# STC32G144K246 register map
Vendor: STC; File version: 2.0
Registers are 8-bit, read-write, no defined reset value unless marked. A register's access mark holds for its fields unless they carry their own. Offsets are from the block's base; [hi:lo] are bit positions; {n}, {i} and the like mark numbered series; 'fields as' and 'values as' point back to an identical list.

## DMA — DMA 公共中断与各通道配置、状态
Base 0x007EF520
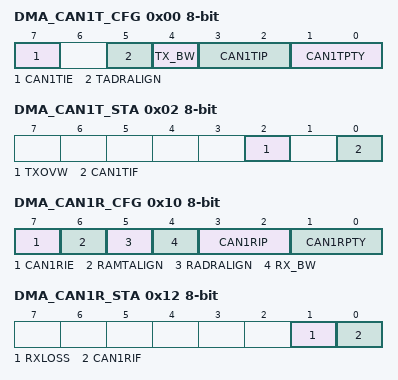
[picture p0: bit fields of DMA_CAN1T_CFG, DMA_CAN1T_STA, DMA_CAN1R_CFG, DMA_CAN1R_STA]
0x00 DMA_CAN1T_CFG ro — CAN1T_DMA配置寄存器
  [7] CAN1TIE — CANnT_DMA 中断使能控制位（n=1/2）
    0=禁止CANnT_DMA 中断; 1=允许CANnT_DMA 中断
  [5] TADRALIGN — CANn 发送DMA 数据对齐控制（n=1/2）
    0=数据不对齐。DMA 缓冲区中的任意两帧数据之间没有空白，数据连续; 1=数据对齐。DMA 缓冲区中的数据必须按DMA_CANnT_FRM 寄存器设置值进行对齐。
  [4] TX_BW — CANn 发送DMA 数据宽度（n=1/2）
    0=8 位宽度（1 字节）; 1=32 位宽度（4 字节）
  [3:2] CAN1TIP — CANnT_DMA 中断优先级控制位（n=1/2）
    0=最低级（0）; 1=较低级（1）; 2=较高级（2）; 3=最高级（3）
  [1:0] CAN1TPTY — CANnT_DMA 数据总线访问优先级控制位（n=1/2）
    0=最低级（0）; 1=较低级（1）; 2=较高级（2）; 3=最高级（3）
0x02 DMA_CAN1T_STA ro — CAN1T_DMA状态寄存器
  [2] TXOVW — 尚未自动匹配到此字段的独立说明；请查看下方章节说明。
  [0] CAN1TIF — CANnT_DMA 中断请求标志位，标志位需软件清零（n=1/2）
0x10 DMA_CAN1R_CFG ro — CAN1R_DMA配置寄存器
  [7] CAN1RIE — CANnR_DMA 中断使能控制位（n=1/2）
    0=禁止CANnR_DMA 中断; 1=允许CANnR_DMA 中断
  [6] RAMTALIGN — CANn 接收DMA 总字节对齐控制（n=1/2）
    0=当接收的数据总字节等于DMA_CANnR_AMT 所设置的值时，DMA 接收完成; 1=当接收的数据总字节大于或等于DMA_CANnR_AMT 所设置的值，且当前帧的所有数据都已传
  [5] RADRALIGN — CANn 接收DMA 数据对齐控制（n=1/2）
    0=数据不对齐。DMA 缓冲区中的任意两帧数据之间没有空白，数据连续; 1=数据对齐。DMA 缓冲区中的数据必须按DMA_CANnR_FRM 寄存器设置值进行对齐。
  [4] RX_BW — CANn 接收DMA 数据宽度（n=1/2）
    0=8 位宽度（1 字节）; 1=32 位宽度（4 字节）
  [3:2] CAN1RIP — CANnR_DMA 中断优先级控制位（n=1/2）
    0=最低级（0）; 1=较低级（1）; 2=较高级（2）; 3=最高级（3）
  [1:0] CAN1RPTY — CANnR_DMA 数据总线访问优先级控制位（n=1/2）
    0=最低级（0）; 1=较低级（1）; 2=较高级（2）; 3=最高级（3）
0x12 DMA_CAN1R_STA ro — CAN1R_DMA状态寄存器
  [1] RXLOSS — 尚未自动匹配到此字段的独立说明；请查看下方章节说明。
  [0] CAN1RIF — CANnR_DMA 中断请求标志位，标志位需软件清零（n=1/2）
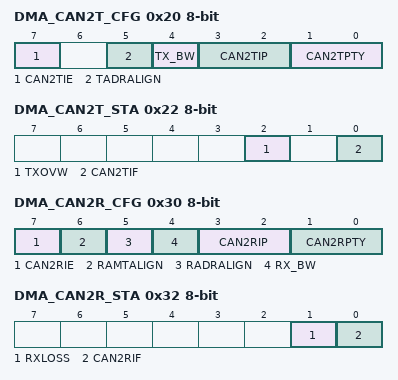
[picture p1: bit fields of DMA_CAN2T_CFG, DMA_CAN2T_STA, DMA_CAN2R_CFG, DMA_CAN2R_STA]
0x20 DMA_CAN2T_CFG ro — CAN2T_DMA配置寄存器
  [7] CAN2TIE — CANnT_DMA 中断使能控制位（n=1/2）
    0=禁止CANnT_DMA 中断; 1=允许CANnT_DMA 中断
  [5] TADRALIGN — CANn 发送DMA 数据对齐控制（n=1/2）
    values as DMA_CAN1T_CFG.TADRALIGN
  [4] TX_BW — CANn 发送DMA 数据宽度（n=1/2）
    0=8 位宽度（1 字节）; 1=32 位宽度（4 字节）
  [3:2] CAN2TIP — CANnT_DMA 中断优先级控制位（n=1/2）
    0=最低级（0）; 1=较低级（1）; 2=较高级（2）; 3=最高级（3）
  [1:0] CAN2TPTY — CANnT_DMA 数据总线访问优先级控制位（n=1/2）
    0=最低级（0）; 1=较低级（1）; 2=较高级（2）; 3=最高级（3）
0x22 DMA_CAN2T_STA ro — CAN2T_DMA状态寄存器
  [2] TXOVW — 尚未自动匹配到此字段的独立说明；请查看下方章节说明。
  [0] CAN2TIF — CANnT_DMA 中断请求标志位，标志位需软件清零（n=1/2）
0x30 DMA_CAN2R_CFG ro — CAN2R_DMA配置寄存器
  [7] CAN2RIE — CANnR_DMA 中断使能控制位（n=1/2）
    0=禁止CANnR_DMA 中断; 1=允许CANnR_DMA 中断
  [6] RAMTALIGN — CANn 接收DMA 总字节对齐控制（n=1/2）
    values as DMA_CAN1R_CFG.RAMTALIGN
  [5] RADRALIGN — CANn 接收DMA 数据对齐控制（n=1/2）
    values as DMA_CAN1R_CFG.RADRALIGN
  [4] RX_BW — CANn 接收DMA 数据宽度（n=1/2）
    0=8 位宽度（1 字节）; 1=32 位宽度（4 字节）
  [3:2] CAN2RIP — CANnR_DMA 中断优先级控制位（n=1/2）
    0=最低级（0）; 1=较低级（1）; 2=较高级（2）; 3=最高级（3）
  [1:0] CAN2RPTY — CANnR_DMA 数据总线访问优先级控制位（n=1/2）
    0=最低级（0）; 1=较低级（1）; 2=较高级（2）; 3=最高级（3）
0x32 DMA_CAN2R_STA ro — CAN2R_DMA状态寄存器
  [1] RXLOSS — 尚未自动匹配到此字段的独立说明；请查看下方章节说明。
  [0] CAN2RIF — CANnR_DMA 中断请求标志位，标志位需软件清零（n=1/2）
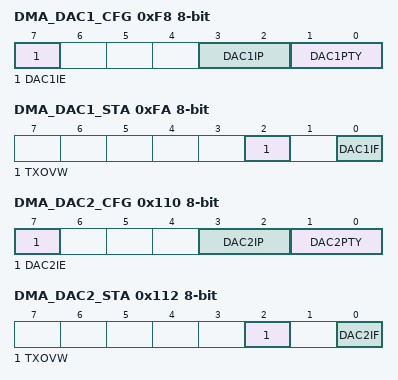
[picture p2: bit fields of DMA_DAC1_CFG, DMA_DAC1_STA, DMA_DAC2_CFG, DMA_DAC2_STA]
0xF8 DMA_DAC1_CFG ro — DAC1_DMA配置寄存器
  [7] DAC1IE — DACn_DMA 中断使能控制位（n=1/2）
    0=禁止DACn_DMA 中断; 1=允许DACn_DMA 中断
  [3:2] DAC1IP — DACn_DMA 中断优先级控制位（n=1/2）
    0=最低级（0）; 1=较低级（1）; 2=较高级（2）; 3=最高级（3）
  [1:0] DAC1PTY — DACn_DMA 数据总线访问优先级控制位（n=1/2）
    0=最低级（0）; 1=较低级（1）; 2=较高级（2）; 3=最高级（3）
0xFA DMA_DAC1_STA ro — DAC1_DMA状态寄存器
  [2] TXOVW — 尚未自动匹配到此字段的独立说明；请查看下方章节说明。
  [0] DAC1IF — DACn_DMA 中断请求标志位，标志位需软件清零（n=1/2）
0x110 DMA_DAC2_CFG ro — DAC2_DMA配置寄存器
  [7] DAC2IE — DACn_DMA 中断使能控制位（n=1/2）
    0=禁止DACn_DMA 中断; 1=允许DACn_DMA 中断
  [3:2] DAC2IP — DACn_DMA 中断优先级控制位（n=1/2）
    0=最低级（0）; 1=较低级（1）; 2=较高级（2）; 3=最高级（3）
  [1:0] DAC2PTY — DACn_DMA 数据总线访问优先级控制位（n=1/2）
    0=最低级（0）; 1=较低级（1）; 2=较高级（2）; 3=最高级（3）
0x112 DMA_DAC2_STA ro — DAC2_DMA状态寄存器
  [2] TXOVW — 尚未自动匹配到此字段的独立说明；请查看下方章节说明。
  [0] DAC2IF — DACn_DMA 中断请求标志位，标志位需软件清零（n=1/2）
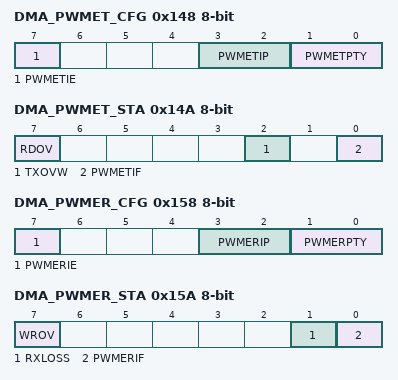
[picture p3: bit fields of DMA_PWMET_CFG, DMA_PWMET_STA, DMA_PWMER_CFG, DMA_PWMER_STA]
0x148 DMA_PWMET_CFG ro — PWMET_DMA配置寄存器
  [7] PWMETIE — PWMnT_DMA 中断使能控制位（n=A/C/E）
    0=禁止PWMnT_DMA 中断; 1=允许PWMnT_DMA 中断
  [3:2] PWMETIP — PWMnT_DMA 中断优先级控制位（n=A/C/E）
    0=最低级（0）; 1=较低级（1）; 2=较高级（2）; 3=最高级（3）
  [1:0] PWMETPTY — PWMnT_DMA 数据总线访问优先级控制位（n=A/C/E）
    0=最低级（0）; 1=较低级（1）; 2=较高级（2）; 3=最高级（3）
0x14A DMA_PWMET_STA ro — PWMET_DMA状态寄存器
  [7] RDOV — 尚未自动匹配到此字段的独立说明；请查看下方章节说明。
  [2] TXOVW — 尚未自动匹配到此字段的独立说明；请查看下方章节说明。
  [0] PWMETIF — PWMnT_DMA 中断请求标志位，标志位需软件清零（n=A/C/E）
0x158 DMA_PWMER_CFG ro — PWMER_DMA配置寄存器
  [7] PWMERIE — PWMnR_DMA 中断使能控制位（n=A/C/E）
    0=禁止PWMnR_DMA 中断; 1=允许PWMnR_DMA 中断
  [3:2] PWMERIP — PWMnR_DMA 中断优先级控制位（n=A/C/E）
    0=最低级（0）; 1=较低级（1）; 2=较高级（2）; 3=最高级（3）
  [1:0] PWMERPTY — PWMnR_DMA 数据总线访问优先级控制位（n=A/C/E）
    0=最低级（0）; 1=较低级（1）; 2=较高级（2）; 3=最高级（3）
0x15A DMA_PWMER_STA ro — PWMER_DMA状态寄存器
  [7] WROV — 尚未自动匹配到此字段的独立说明；请查看下方章节说明。
  [1] RXLOSS — 尚未自动匹配到此字段的独立说明；请查看下方章节说明。
  [0] PWMERIF — PWMnR_DMA 中断请求标志位，标志位需软件清零（n=A/C/E）
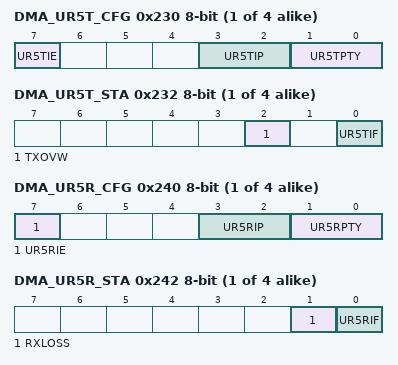
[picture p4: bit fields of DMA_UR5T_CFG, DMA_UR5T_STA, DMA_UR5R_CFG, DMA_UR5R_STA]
{0x140+0x30*i} DMA_UR{i}T_CFG ro (i=5..8) — UR{i}T_DMA配置寄存器
  [7] UR{i}TIE — URnT_DMA 中断使能控制位（n=1/2/3/4/5/6/7/8）
    0=禁止URnT_DMA 中断; 1=允许URnT_DMA 中断
  [3:2] UR{i}TIP — URnT_DMA 中断优先级控制位（n=1/2/3/4/5/6/7/8）
    0=最低级（0）; 1=较低级（1）; 2=较高级（2）; 3=最高级（3）
  [1:0] UR{i}TPTY — URnT_DMA 数据总线访问优先级控制位（n=1/2/3/4/5/6/7/8）
    0=最低级（0）; 1=较低级（1）; 2=较高级（2）; 3=最高级（3）
{0x142+0x30*i} DMA_UR{i}T_STA ro (i=5..8) — UR{i}T_DMA状态寄存器
  [2] TXOVW — 尚未自动匹配到此字段的独立说明；请查看下方章节说明。
  [0] UR{i}TIF — URnT_DMA 中断请求标志位，标志位需软件清零（n=1/2/3/4/5/6/7/8）
{0x150+0x30*i} DMA_UR{i}R_CFG ro (i=5..8) — UR{i}R_DMA配置寄存器
  [7] UR{i}RIE — URnR_DMA 中断使能控制位（n=1/2/3/4/5/6/7/8）
    0=禁止URnR_DMA 中断; 1=允许URnR_DMA 中断
  [3:2] UR{i}RIP — URnR_DMA 中断优先级控制位（n=1/2/3/4/5/6/7/8）
    0=最低级（0）; 1=较低级（1）; 2=较高级（2）; 3=最高级（3）
  [1:0] UR{i}RPTY — URnR_DMA 数据总线访问优先级控制位（n=1/2/3/4/5/6/7/8）
    0=最低级（0）; 1=较低级（1）; 2=较高级（2）; 3=最高级（3）
{0x152+0x30*i} DMA_UR{i}R_STA ro (i=5..8) — UR{i}R_DMA状态寄存器
  [1] RXLOSS — 尚未自动匹配到此字段的独立说明；请查看下方章节说明。
  [0] UR{i}RIF — URnR_DMA 中断请求标志位，标志位需软件清零（n=1/2/3/4/5/6/7/8）
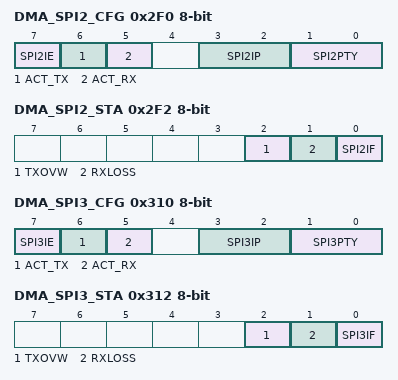
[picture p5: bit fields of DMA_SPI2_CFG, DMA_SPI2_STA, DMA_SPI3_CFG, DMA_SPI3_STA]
0x2F0 DMA_SPI2_CFG ro — SPI2_DMA配置寄存器
  [7] SPI2IE — SPIn_DMA 中断使能控制位（n=1/2/3）
    0=禁止SPIn_DMA 中断; 1=允许SPIn_DMA 中断
  [6] ACT_TX — 尚未自动匹配到此字段的独立说明；请查看下方章节说明。
  [5] ACT_RX — 尚未自动匹配到此字段的独立说明；请查看下方章节说明。
  [3:2] SPI2IP — 尚未自动匹配到此字段的独立说明；请查看下方章节说明。
    0=最低级（0）; 1=较低级（1）; 2=较高级（2）; 3=最高级（3）
  [1:0] SPI2PTY — SPIn_DMA 数据总线访问优先级控制位（n=1/2/3）
    0=最低级（0）; 1=较低级（1）; 2=较高级（2）; 3=最高级（3）
0x2F2 DMA_SPI2_STA ro — SPI2_DMA状态寄存器
  [2] TXOVW — 尚未自动匹配到此字段的独立说明；请查看下方章节说明。
  [1] RXLOSS — 尚未自动匹配到此字段的独立说明；请查看下方章节说明。
  [0] SPI2IF — SPIn_DMA 中断请求标志位，当SPIn_DMA 数据交换完成后，硬件自动将SPInIF 置1，若使能 SPIn_DMA 中断则进入中断服务程序。标志位需软件清零（n=1/2/3）
0x310 DMA_SPI3_CFG ro — SPI3_DMA配置寄存器
  [7] SPI3IE — SPIn_DMA 中断使能控制位（n=1/2/3）
    0=禁止SPIn_DMA 中断; 1=允许SPIn_DMA 中断
  [6] ACT_TX — 尚未自动匹配到此字段的独立说明；请查看下方章节说明。
  [5] ACT_RX — 尚未自动匹配到此字段的独立说明；请查看下方章节说明。
  [3:2] SPI3IP — 尚未自动匹配到此字段的独立说明；请查看下方章节说明。
    0=最低级（0）; 1=较低级（1）; 2=较高级（2）; 3=最高级（3）
  [1:0] SPI3PTY — SPIn_DMA 数据总线访问优先级控制位（n=1/2/3）
    0=最低级（0）; 1=较低级（1）; 2=较高级（2）; 3=最高级（3）
0x312 DMA_SPI3_STA ro — SPI3_DMA状态寄存器
  [2] TXOVW — 尚未自动匹配到此字段的独立说明；请查看下方章节说明。
  [1] RXLOSS — 尚未自动匹配到此字段的独立说明；请查看下方章节说明。
  [0] SPI3IF — SPIn_DMA 中断请求标志位，当SPIn_DMA 数据交换完成后，硬件自动将SPInIF 置1，若使能 SPIn_DMA 中断则进入中断服务程序。标志位需软件清零（n=1/2/3）
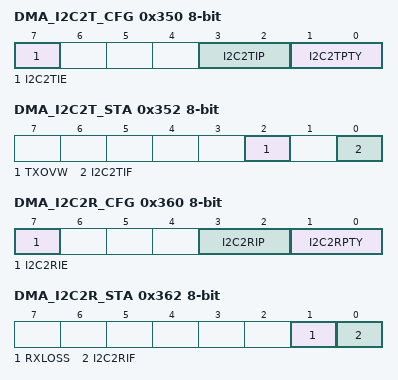
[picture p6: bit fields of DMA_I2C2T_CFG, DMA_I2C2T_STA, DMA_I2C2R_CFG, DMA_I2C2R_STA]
0x350 DMA_I2C2T_CFG ro — I2C2T_DMA配置寄存器
  [7] I2C2TIE — I2CnT_DMA 中断使能控制位（n=1/2）
    0=禁止I2CnT_DMA 中断; 1=允许I2CnT_DMA 中断
  [3:2] I2C2TIP — I2CnT_DMA 中断优先级控制位（n=1/2）
    0=最低级（0）; 1=较低级（1）; 2=较高级（2）; 3=最高级（3）
  [1:0] I2C2TPTY — I2CnT_DMA 数据总线访问优先级控制位（n=1/2）
    0=最低级（0）; 1=较低级（1）; 2=较高级（2）; 3=最高级（3）
0x352 DMA_I2C2T_STA ro — I2C2T_DMA状态寄存器
  [2] TXOVW — 尚未自动匹配到此字段的独立说明；请查看下方章节说明。
  [0] I2C2TIF — I2CnT_DMA 中断请求标志位，标志位需软件清零（n=1/2）
0x360 DMA_I2C2R_CFG ro — I2C2R_DMA配置寄存器
  [7] I2C2RIE — I2CnR_DMA 中断使能控制位（n=1/2）
    0=禁止I2CnR_DMA 中断; 1=允许I2CnR_DMA 中断
  [3:2] I2C2RIP — I2CnR_DMA 中断优先级控制位（n=1/2）
    0=最低级（0）; 1=较低级（1）; 2=较高级（2）; 3=最高级（3）
  [1:0] I2C2RPTY — I2CnR_DMA 数据总线访问优先级控制位（n=1/2）
    0=最低级（0）; 1=较低级（1）; 2=较高级（2）; 3=最高级（3）
0x362 DMA_I2C2R_STA ro — I2C2R_DMA状态寄存器
  [1] RXLOSS — 尚未自动匹配到此字段的独立说明；请查看下方章节说明。
  [0] I2C2RIF — I2CnR_DMA 中断请求标志位，标志位需软件清零（n=1/2）
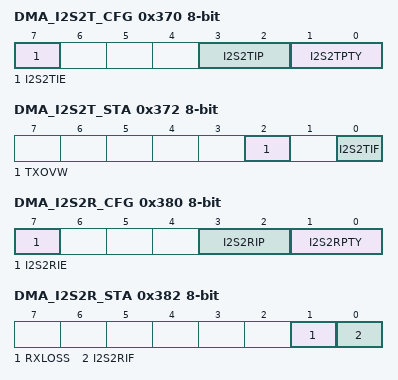
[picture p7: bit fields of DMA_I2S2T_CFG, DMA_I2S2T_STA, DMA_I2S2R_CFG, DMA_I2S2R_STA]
0x370 DMA_I2S2T_CFG ro — I2S2T_DMA配置寄存器
  [7] I2S2TIE — I2SnT_DMA 中断使能控制位（n=1/2）
    0=禁止I2SnT_DMA 中断; 1=允许I2SnT_DMA 中断
  [3:2] I2S2TIP — I2SnT_DMA 中断优先级控制位（n=1/2）
    0=最低级（0）; 1=较低级（1）; 2=较高级（2）; 3=最高级（3）
  [1:0] I2S2TPTY — I2SnT_DMA 数据总线访问优先级控制位（n=1/2）
    0=最低级（0）; 1=较低级（1）; 2=较高级（2）; 3=最高级（3）
0x372 DMA_I2S2T_STA ro — I2S2T_DMA状态寄存器
  [2] TXOVW — 尚未自动匹配到此字段的独立说明；请查看下方章节说明。
  [0] I2S2TIF — I2SnT_DMA 中断请求标志位，标志位需软件清零（n=1/2）
0x380 DMA_I2S2R_CFG ro — I2S2R_DMA配置寄存器
  [7] I2S2RIE — I2SnR_DMA 中断使能控制位（n=1/2）
    0=禁止I2SnR_DMA 中断; 1=允许I2SnR_DMA 中断
  [3:2] I2S2RIP — I2SnR_DMA 中断优先级控制位（n=1/2）
    0=最低级（0）; 1=较低级（1）; 2=较高级（2）; 3=最高级（3）
  [1:0] I2S2RPTY — I2SnR_DMA 数据总线访问优先级控制位（n=1/2）
    0=最低级（0）; 1=较低级（1）; 2=较高级（2）; 3=最高级（3）
0x382 DMA_I2S2R_STA ro — I2S2R_DMA状态寄存器
  [1] RXLOSS — 尚未自动匹配到此字段的独立说明；请查看下方章节说明。
  [0] I2S2RIF — I2SnR_DMA 中断请求标志位，标志位需软件清零（n=1/2）
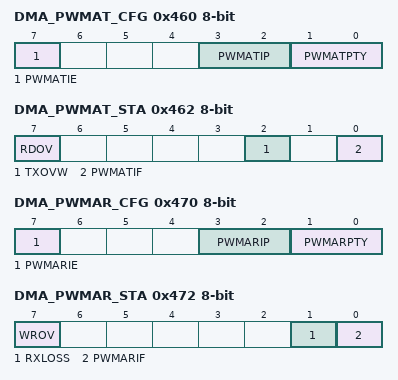
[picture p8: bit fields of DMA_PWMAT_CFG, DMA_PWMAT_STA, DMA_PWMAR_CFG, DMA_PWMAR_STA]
0x460 DMA_PWMAT_CFG ro — PWMAT_DMA配置寄存器
  [7] PWMATIE — PWMnT_DMA 中断使能控制位（n=A/C/E）
    0=禁止PWMnT_DMA 中断; 1=允许PWMnT_DMA 中断
  [3:2] PWMATIP — PWMnT_DMA 中断优先级控制位（n=A/C/E）
    0=最低级（0）; 1=较低级（1）; 2=较高级（2）; 3=最高级（3）
  [1:0] PWMATPTY — PWMnT_DMA 数据总线访问优先级控制位（n=A/C/E）
    0=最低级（0）; 1=较低级（1）; 2=较高级（2）; 3=最高级（3）
0x462 DMA_PWMAT_STA ro — PWMAT_DMA状态寄存器
  [7] RDOV — 尚未自动匹配到此字段的独立说明；请查看下方章节说明。
  [2] TXOVW — 尚未自动匹配到此字段的独立说明；请查看下方章节说明。
  [0] PWMATIF — PWMnT_DMA 中断请求标志位，标志位需软件清零（n=A/C/E）
0x470 DMA_PWMAR_CFG ro — PWMAR_DMA配置寄存器
  [7] PWMARIE — PWMnR_DMA 中断使能控制位（n=A/C/E）
    0=禁止PWMnR_DMA 中断; 1=允许PWMnR_DMA 中断
  [3:2] PWMARIP — PWMnR_DMA 中断优先级控制位（n=A/C/E）
    0=最低级（0）; 1=较低级（1）; 2=较高级（2）; 3=最高级（3）
  [1:0] PWMARPTY — PWMnR_DMA 数据总线访问优先级控制位（n=A/C/E）
    0=最低级（0）; 1=较低级（1）; 2=较高级（2）; 3=最高级（3）
0x472 DMA_PWMAR_STA ro — PWMAR_DMA状态寄存器
  [7] WROV — 尚未自动匹配到此字段的独立说明；请查看下方章节说明。
  [1] RXLOSS — 尚未自动匹配到此字段的独立说明；请查看下方章节说明。
  [0] PWMARIF — PWMnR_DMA 中断请求标志位，标志位需软件清零（n=A/C/E）
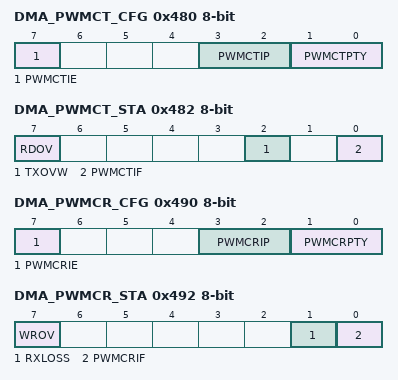
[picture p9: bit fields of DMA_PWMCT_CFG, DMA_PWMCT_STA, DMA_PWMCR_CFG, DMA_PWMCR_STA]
0x480 DMA_PWMCT_CFG ro — PWMCT_DMA配置寄存器
  [7] PWMCTIE — PWMnT_DMA 中断使能控制位（n=A/C/E）
    0=禁止PWMnT_DMA 中断; 1=允许PWMnT_DMA 中断
  [3:2] PWMCTIP — PWMnT_DMA 中断优先级控制位（n=A/C/E）
    0=最低级（0）; 1=较低级（1）; 2=较高级（2）; 3=最高级（3）
  [1:0] PWMCTPTY — PWMnT_DMA 数据总线访问优先级控制位（n=A/C/E）
    0=最低级（0）; 1=较低级（1）; 2=较高级（2）; 3=最高级（3）
0x482 DMA_PWMCT_STA ro — PWMCT_DMA状态寄存器
  [7] RDOV — 尚未自动匹配到此字段的独立说明；请查看下方章节说明。
  [2] TXOVW — 尚未自动匹配到此字段的独立说明；请查看下方章节说明。
  [0] PWMCTIF — PWMnT_DMA 中断请求标志位，标志位需软件清零（n=A/C/E）
0x490 DMA_PWMCR_CFG ro — PWMCR_DMA配置寄存器
  [7] PWMCRIE — PWMnR_DMA 中断使能控制位（n=A/C/E）
    0=禁止PWMnR_DMA 中断; 1=允许PWMnR_DMA 中断
  [3:2] PWMCRIP — PWMnR_DMA 中断优先级控制位（n=A/C/E）
    0=最低级（0）; 1=较低级（1）; 2=较高级（2）; 3=最高级（3）
  [1:0] PWMCRPTY — PWMnR_DMA 数据总线访问优先级控制位（n=A/C/E）
    0=最低级（0）; 1=较低级（1）; 2=较高级（2）; 3=最高级（3）
0x492 DMA_PWMCR_STA ro — PWMCR_DMA状态寄存器
  [7] WROV — 尚未自动匹配到此字段的独立说明；请查看下方章节说明。
  [1] RXLOSS — 尚未自动匹配到此字段的独立说明；请查看下方章节说明。
  [0] PWMCRIF — PWMnR_DMA 中断请求标志位，标志位需软件清零（n=A/C/E）
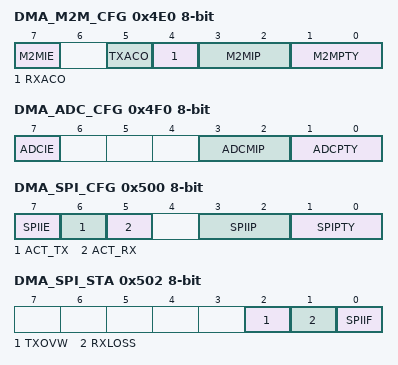
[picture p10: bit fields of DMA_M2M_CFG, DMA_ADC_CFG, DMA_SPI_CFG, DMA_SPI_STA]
0x4E0 DMA_M2M_CFG ro — M2M_DMA配置寄存器
  [7] M2MIE — M2M_DMA 中断使能控制位
    0=禁止M2M_DMA 中断; 1=允许M2M_DMA 中断
  [5] TXACO — M2M_DMA 源地址（读取地址）改变方向
    0=数据读取完成后地址自动递增; 1=数据读取完成后地址自动递减
  [4] RXACO — M2M_DMA 目标地址（写入地址）改变方向
    0=数据写入完成后地址自动递增; 1=数据写入完成后地址自动递减
  [3:2] M2MIP — M2M_DMA 中断优先级控制位
    0=最低级（0）; 1=较低级（1）; 2=较高级（2）; 3=最高级（3）
  [1:0] M2MPTY — M2M_DMA 数据总线访问优先级控制位
    0=最低级（0）; 1=较低级（1）; 2=较高级（2）; 3=最高级（3）
0x4E2 DMA_M2M_STA ro — M2M_DMA状态寄存器
  [0] M2MIF — M2M_DMA 中断请求标志位，标志位需软件清零
0x4F0 DMA_ADC_CFG ro — ADC_DMA配置寄存器
  [7] ADCIE — 尚未自动匹配到此字段的独立说明；请查看下方章节说明。
  [3:2] ADCMIP — 尚未自动匹配到此字段的独立说明；请查看下方章节说明。
  [1:0] ADCPTY — 尚未自动匹配到此字段的独立说明；请查看下方章节说明。
0x4F2 DMA_ADC_STA ro — ADC_DMA状态寄存器
  [0] ADCIF — 尚未自动匹配到此字段的独立说明；请查看下方章节说明。
0x500 DMA_SPI_CFG ro — SPI_DMA配置寄存器
  [7] SPIIE — 尚未自动匹配到此字段的独立说明；请查看下方章节说明。
  [6] ACT_TX — 尚未自动匹配到此字段的独立说明；请查看下方章节说明。
  [5] ACT_RX — 尚未自动匹配到此字段的独立说明；请查看下方章节说明。
  [3:2] SPIIP — 尚未自动匹配到此字段的独立说明；请查看下方章节说明。
  [1:0] SPIPTY — 尚未自动匹配到此字段的独立说明；请查看下方章节说明。
0x502 DMA_SPI_STA ro — SPI_DMA状态寄存器
  [2] TXOVW — 尚未自动匹配到此字段的独立说明；请查看下方章节说明。
  [1] RXLOSS — 尚未自动匹配到此字段的独立说明；请查看下方章节说明。
  [0] SPIIF — 尚未自动匹配到此字段的独立说明；请查看下方章节说明。
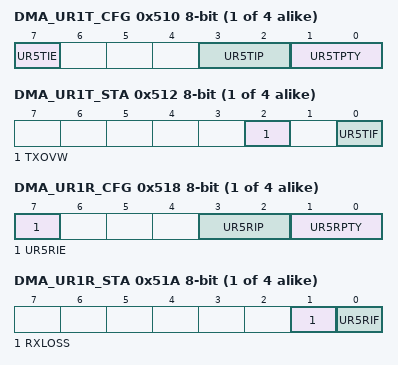
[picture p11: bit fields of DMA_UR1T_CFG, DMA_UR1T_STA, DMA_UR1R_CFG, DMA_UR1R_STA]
{0x500+0x10*i} DMA_UR{i}T_CFG ro (i=1..4) — UR{i}T_DMA配置寄存器
  fields as DMA_UR5T_CFG
{0x502+0x10*i} DMA_UR{i}T_STA ro (i=1..4) — UR{i}T_DMA状态寄存器
  fields as DMA_UR5T_STA
{0x508+0x10*i} DMA_UR{i}R_CFG ro (i=1..4) — UR{i}R_DMA配置寄存器
  fields as DMA_UR5R_CFG
{0x50A+0x10*i} DMA_UR{i}R_STA ro (i=1..4) — UR{i}R_DMA状态寄存器
  fields as DMA_UR5R_STA
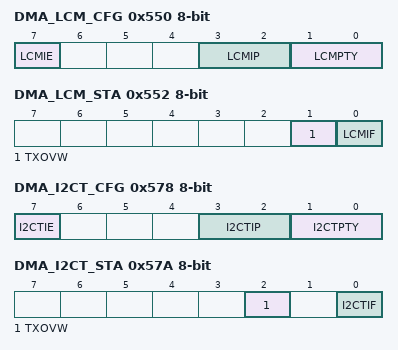
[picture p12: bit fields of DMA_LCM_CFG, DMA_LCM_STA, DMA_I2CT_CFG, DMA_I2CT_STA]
0x550 DMA_LCM_CFG ro — LCM_DMA配置寄存器
  [7] LCMIE — TFT 彩屏DMA 中断使能控制位
    0=禁止TFT 彩屏DMA 中断; 1=允许TFT 彩屏DMA 中断
  [3:2] LCMIP — TFT 彩屏DMA 中断优先级控制位
    0=最低级（0）; 1=较低级（1）; 2=较高级（2）; 3=最高级（3）
  [1:0] LCMPTY — TFT 彩屏DMA 数据总线访问优先级控制位
    0=最低级（0）; 1=较低级（1）; 2=较高级（2）; 3=最高级（3）
0x552 DMA_LCM_STA ro — LCM_DMA状态寄存器
  [1] TXOVW — TFT 彩屏DMA 数据覆盖标志位。TFT 彩屏DMA 正在数据传输过程中，LCMIF 写LCMIFDATL 和LCMIFDATH 寄存器时，会导致数据传输失败，此时硬件硬件自动将TXOVW 置1。标志位需软 件清零
  [0] LCMIF — TFT 彩屏DMA 中断请求标志位，标志位需软件清零
0x578 DMA_I2CT_CFG ro — I2CT_DMA配置寄存器
  [7] I2CTIE — 尚未自动匹配到此字段的独立说明；请查看下方章节说明。
  [3:2] I2CTIP — 尚未自动匹配到此字段的独立说明；请查看下方章节说明。
  [1:0] I2CTPTY — 尚未自动匹配到此字段的独立说明；请查看下方章节说明。
0x57A DMA_I2CT_STA ro — I2CT_DMA状态寄存器
  [2] TXOVW — 尚未自动匹配到此字段的独立说明；请查看下方章节说明。
  [0] I2CTIF — 尚未自动匹配到此字段的独立说明；请查看下方章节说明。
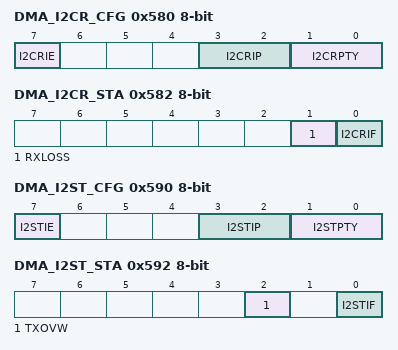
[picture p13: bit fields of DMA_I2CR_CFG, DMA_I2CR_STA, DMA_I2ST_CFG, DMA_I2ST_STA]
0x580 DMA_I2CR_CFG ro — I2CR_DMA配置寄存器
  [7] I2CRIE — 尚未自动匹配到此字段的独立说明；请查看下方章节说明。
  [3:2] I2CRIP — 尚未自动匹配到此字段的独立说明；请查看下方章节说明。
  [1:0] I2CRPTY — 尚未自动匹配到此字段的独立说明；请查看下方章节说明。
0x582 DMA_I2CR_STA ro — I2CR_DMA状态寄存器
  [1] RXLOSS — 尚未自动匹配到此字段的独立说明；请查看下方章节说明。
  [0] I2CRIF — 尚未自动匹配到此字段的独立说明；请查看下方章节说明。
0x590 DMA_I2ST_CFG ro — I2ST_DMA配置寄存器
  [7] I2STIE — 尚未自动匹配到此字段的独立说明；请查看下方章节说明。
  [3:2] I2STIP — 尚未自动匹配到此字段的独立说明；请查看下方章节说明。
  [1:0] I2STPTY — 尚未自动匹配到此字段的独立说明；请查看下方章节说明。
0x592 DMA_I2ST_STA ro — I2ST_DMA状态寄存器
  [2] TXOVW — 尚未自动匹配到此字段的独立说明；请查看下方章节说明。
  [0] I2STIF — 尚未自动匹配到此字段的独立说明；请查看下方章节说明。
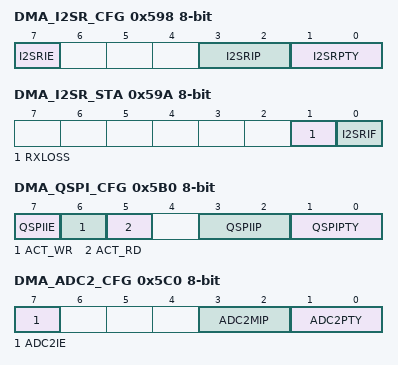
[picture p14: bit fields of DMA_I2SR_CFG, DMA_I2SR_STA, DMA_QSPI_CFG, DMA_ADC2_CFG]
0x598 DMA_I2SR_CFG ro — I2SR_DMA配置寄存器
  [7] I2SRIE — 尚未自动匹配到此字段的独立说明；请查看下方章节说明。
  [3:2] I2SRIP — 尚未自动匹配到此字段的独立说明；请查看下方章节说明。
  [1:0] I2SRPTY — 尚未自动匹配到此字段的独立说明；请查看下方章节说明。
0x59A DMA_I2SR_STA ro — I2SR_DMA状态寄存器
  [1] RXLOSS — 尚未自动匹配到此字段的独立说明；请查看下方章节说明。
  [0] I2SRIF — 尚未自动匹配到此字段的独立说明；请查看下方章节说明。
0x5B0 DMA_QSPI_CFG ro — QSPI_DMA配置寄存器
  [7] QSPIIE — QSPI_DMA 中断使能控制位
    0=禁止QSPI_DMA 中断; 1=允许QSPI_DMA 中断
  [6] ACT_WR — QSPI_DMA 写数据控制位
    0=禁止QSPI_DMA 写数据。; 1=允许QSPI_DMA 写数据。
  [5] ACT_RD — QSPI_DMA 读数据控制位
    0=禁止QSPI_DMA 读数据。; 1=允许QSPI_DMA 读数据。
  [3:2] QSPIIP — QSPI_DMA 中断优先级控制位
    0=最低级（0）; 1=较低级（1）; 2=较高级（2）; 3=最高级（3）
  [1:0] QSPIPTY — QSPI_DMA 数据总线访问优先级控制位
    0=最低级（0）; 1=较低级（1）; 2=较高级（2）; 3=最高级（3）
0x5B2 DMA_QSPI_STA ro — QSPI_DMA状态寄存器
  [0] QSPIIF — QSPI_DMA 中断请求标志位，标志位需软件清零
0x5C0 DMA_ADC2_CFG ro — ADC2_DMA配置寄存器
  [7] ADC2IE — ADCn_DMA 中断使能控制位（n=1/2）
    0=禁止ADCn_DMA 中断; 1=允许ADCn_DMA 中断
  [3:2] ADC2MIP — 尚未自动匹配到此字段的独立说明；请查看下方章节说明。
  [1:0] ADC2PTY — ADCn_DMA 数据总线访问优先级控制位（n=1/2）
    0=最低级（0）; 1=较低级（1）; 2=较高级（2）; 3=最高级（3）
0x5C2 DMA_ADC2_STA ro — ADC2_DMA状态寄存器
  [0] ADC2IF — ADCn_DMA 中断请求标志位，标志位需软件清零（n=1/2）
0x5D8 DMA_ARB_CFG ro — DMA仲裁配置寄存器
  [7] WTRREN — 尚未自动匹配到此字段的独立说明；请查看下方章节说明。
  [3:0] STASEL — 尚未自动匹配到此字段的独立说明；请查看下方章节说明。
0x5D9 DMA_ARB_STA ro — DMA仲裁状态寄存器
  [7:0] ARB_STA — 尚未自动匹配到此字段的独立说明；请查看下方章节说明。
0xF810BCD DMAIR ro — FMUDMA指令寄存器
  [7:0] DMAIR — 尚未自动匹配到此字段的独立说明；请查看下方章节说明。
